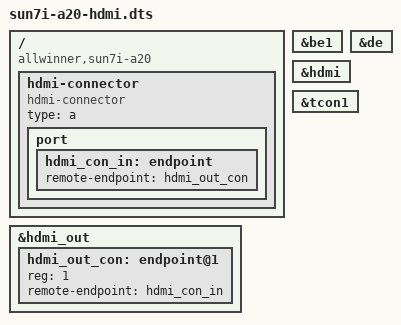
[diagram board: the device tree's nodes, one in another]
/dts-v1/;
/plugin/;

/ {
	compatible = "allwinner,sun7i-a20";

	fragment@0 {
		target-path = "/";
		__overlay__ {
			hdmi-connector {
				compatible = "hdmi-connector";
				type = "a";

				port {
					hdmi_con_in: endpoint {
						remote-endpoint = <&hdmi_out_con>;
					};
				};
			};
		};
	};

	fragment@1 {
		target = <&be1>;
		__overlay__ {
			status = "okay";
		};
	};

	fragment@2 {
		target = <&de>;
		__overlay__ {
			status = "okay";
		};
	};

	fragment@3 {
		target = <&hdmi>;
		__overlay__ {
			status = "okay";
		};
	};

	fragment@4 {
		target = <&tcon1>;
		__overlay__ {
			status = "okay";
		};
	};

	fragment@5 {
		target = <&hdmi_out>;
		__overlay__ {
			hdmi_out_con: endpoint@1 {
				reg = <1>;
				remote-endpoint = <&hdmi_con_in>;
			};
		};
	};
};
